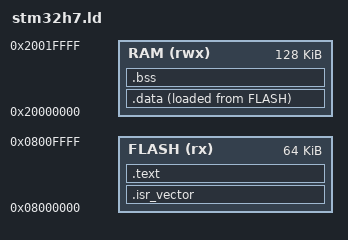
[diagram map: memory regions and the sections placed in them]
/* Minimal linker script for STM32H7 RTT demo.
 * FLASH @ 0x08000000, RAM = DTCM @ 0x20000000.
 * RTT control block (.rtt_cb) placed at RAM start so J-Link auto-finds it.
 */
ENTRY(Reset_Handler)

MEMORY
{
  FLASH (rx) : ORIGIN = 0x08000000, LENGTH = 64K
  RAM   (rwx): ORIGIN = 0x20000000, LENGTH = 128K
}

_estack = ORIGIN(RAM) + LENGTH(RAM);

SECTIONS
{
  .isr_vector :
  {
    KEEP(*(.isr_vector))
  } > FLASH

  .text :
  {
    *(.text*)
    *(.rodata*)
  } > FLASH

  _sidata = LOADADDR(.data);

  .data :
  {
    _sdata = .;
    *(.data*)
    KEEP(*(.rtt_cb))   /* RTT control block: initialized data, copied by startup */
    _edata = .;
  } > RAM AT> FLASH

  .bss :
  {
    _sbss = .;
    *(.bss*)
    *(COMMON)
    _ebss = .;
  } > RAM

  /DISCARD/ :
  {
    *(.ARM.exidx*)
    *(.comment*)
  }
}
